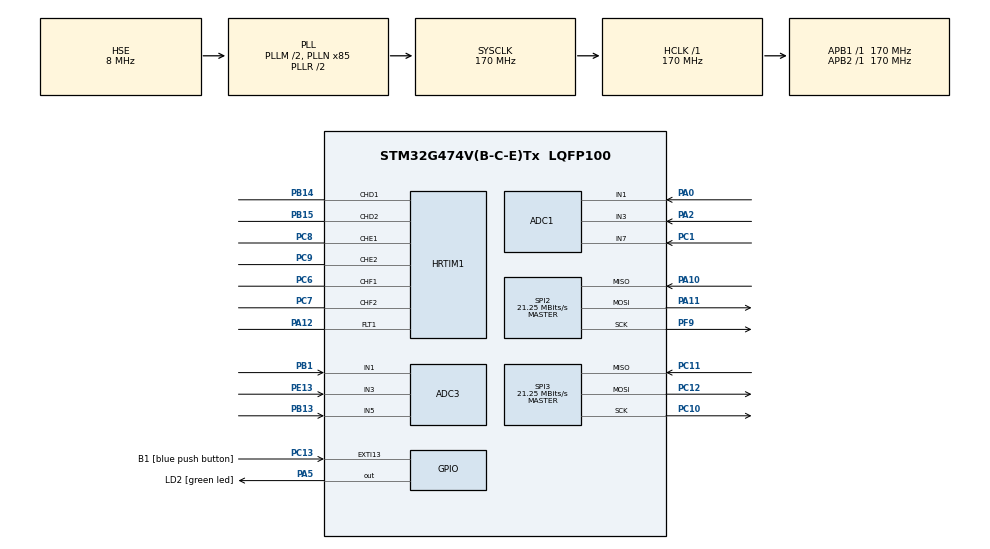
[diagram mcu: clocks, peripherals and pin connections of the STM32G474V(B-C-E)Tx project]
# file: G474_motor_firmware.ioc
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ADC1.AWD1HighThreshold=3
ADC1.AWD1ITMode=ENABLE
ADC1.ContinuousConvMode=ENABLE
ADC1.DMAContinuousRequests=ENABLE
ADC1.EOCSelection=ADC_EOC_SEQ_CONV
ADC1.EnableAnalogWatchDog1=true
ADC1.EnableInjectedConversion=ENABLE
ADC1.EnableInjectedOversampling=ENABLE
ADC1.EnableRegularConversion=DISABLE
ADC1.ExternalTrigInjecConv=ADC_EXTERNALTRIGINJEC_HRTIM_TRG2
ADC1.InjNumberOfConversion=3
ADC1.InjOversamplingRatio=ADC_OVERSAMPLING_RATIO_4
ADC1.InjOversamplingRightShift=ADC_RIGHTBITSHIFT_2
ADC1.InjectedChannel-1\#ChannelInjectedConversion=ADC_CHANNEL_1
ADC1.InjectedChannel-2\#ChannelInjectedConversion=ADC_CHANNEL_1
ADC1.InjectedChannel-3\#ChannelInjectedConversion=ADC_CHANNEL_1
ADC1.InjectedOffsetNumber-1\#ChannelInjectedConversion=ADC_OFFSET_NONE
ADC1.InjectedOffsetNumber-2\#ChannelInjectedConversion=ADC_OFFSET_NONE
ADC1.InjectedOffsetNumber-3\#ChannelInjectedConversion=ADC_OFFSET_NONE
ADC1.InjectedRank-1\#ChannelInjectedConversion=1
ADC1.InjectedRank-2\#ChannelInjectedConversion=2
ADC1.InjectedRank-3\#ChannelInjectedConversion=3
ADC1.InjectedSamplingTime-1\#ChannelInjectedConversion=ADC_SAMPLETIME_2CYCLES_5
ADC1.InjectedSamplingTime-2\#ChannelInjectedConversion=ADC_SAMPLETIME_2CYCLES_5
ADC1.InjectedSamplingTime-3\#ChannelInjectedConversion=ADC_SAMPLETIME_2CYCLES_5
ADC1.Rank1_Channel=ADC_CHANNEL_1
ADC1.Rank2_Channel=ADC_CHANNEL_1
ADC1.Rank3_Channel=ADC_CHANNEL_1
ADC1.WatchdogMode=ADC_ANALOGWATCHDOG_ALL_REGINJEC
ADC1.master=1
ADC3.AWD1HighThreshold=3
ADC3.AWD1ITMode=ENABLE
ADC3.ContinuousConvMode=ENABLE
ADC3.DMAContinuousRequests=ENABLE
ADC3.EOCSelection=ADC_EOC_SEQ_CONV
ADC3.EnableAnalogWatchDog1=true
ADC3.EnableInjectedConversion=ENABLE
ADC3.EnableInjectedOversampling=ENABLE
ADC3.EnableRegularConversion=DISABLE
ADC3.ExternalTrigInjecConv=ADC_EXTERNALTRIGINJEC_HRTIM_TRG2
ADC3.InjNumberOfConversion=3
ADC3.InjOversamplingRatio=ADC_OVERSAMPLING_RATIO_4
ADC3.InjOversamplingRightShift=ADC_RIGHTBITSHIFT_2
ADC3.InjectedChannel-1\#ChannelInjectedConversion=ADC_CHANNEL_1
ADC3.InjectedChannel-2\#ChannelInjectedConversion=ADC_CHANNEL_1
ADC3.InjectedChannel-3\#ChannelInjectedConversion=ADC_CHANNEL_1
ADC3.InjectedOffsetNumber-1\#ChannelInjectedConversion=ADC_OFFSET_NONE
ADC3.InjectedOffsetNumber-2\#ChannelInjectedConversion=ADC_OFFSET_NONE
ADC3.InjectedOffsetNumber-3\#ChannelInjectedConversion=ADC_OFFSET_NONE
ADC3.InjectedRank-1\#ChannelInjectedConversion=1
ADC3.InjectedRank-2\#ChannelInjectedConversion=2
ADC3.InjectedRank-3\#ChannelInjectedConversion=3
ADC3.InjectedSamplingTime-1\#ChannelInjectedConversion=ADC_SAMPLETIME_2CYCLES_5
ADC3.InjectedSamplingTime-2\#ChannelInjectedConversion=ADC_SAMPLETIME_2CYCLES_5
ADC3.InjectedSamplingTime-3\#ChannelInjectedConversion=ADC_SAMPLETIME_2CYCLES_5
ADC3.Rank1_Channel=ADC_CHANNEL_1
ADC3.Rank2_Channel=ADC_CHANNEL_1
ADC3.Rank3_Channel=ADC_CHANNEL_1
ADC3.WatchdogMode=ADC_ANALOGWATCHDOG_ALL_REGINJEC
ADC3.master=1
Dma.ADC1.0.Direction=DMA_PERIPH_TO_MEMORY
Dma.ADC1.0.EventEnable=DISABLE
Dma.ADC1.0.Instance=DMA1_Channel1
Dma.ADC1.0.MemDataAlignment=DMA_MDATAALIGN_HALFWORD
Dma.ADC1.0.MemInc=DMA_MINC_ENABLE
Dma.ADC1.0.Mode=DMA_CIRCULAR
Dma.ADC1.0.PeriphDataAlignment=DMA_PDATAALIGN_HALFWORD
Dma.ADC1.0.PeriphInc=DMA_PINC_DISABLE
Dma.ADC1.0.Polarity=HAL_DMAMUX_REQ_GEN_RISING
Dma.ADC1.0.Priority=DMA_PRIORITY_VERY_HIGH
Dma.ADC1.0.RequestNumber=1
Dma.ADC1.0.SignalID=NONE
Dma.ADC1.0.SyncEnable=DISABLE
Dma.ADC1.0.SyncPolarity=HAL_DMAMUX_SYNC_NO_EVENT
Dma.ADC1.0.SyncRequestNumber=1
Dma.ADC1.0.SyncSignalID=NONE
Dma.ADC3.1.Direction=DMA_PERIPH_TO_MEMORY
Dma.ADC3.1.EventEnable=DISABLE
Dma.ADC3.1.Instance=DMA1_Channel2
Dma.ADC3.1.MemDataAlignment=DMA_MDATAALIGN_HALFWORD
Dma.ADC3.1.MemInc=DMA_MINC_ENABLE
Dma.ADC3.1.Mode=DMA_CIRCULAR
Dma.ADC3.1.PeriphDataAlignment=DMA_PDATAALIGN_HALFWORD
Dma.ADC3.1.PeriphInc=DMA_PINC_DISABLE
Dma.ADC3.1.Polarity=HAL_DMAMUX_REQ_GEN_RISING
Dma.ADC3.1.Priority=DMA_PRIORITY_VERY_HIGH
Dma.ADC3.1.RequestNumber=1
Dma.ADC3.1.SignalID=NONE
Dma.ADC3.1.SyncEnable=DISABLE
Dma.ADC3.1.SyncPolarity=HAL_DMAMUX_SYNC_NO_EVENT
Dma.ADC3.1.SyncRequestNumber=1
Dma.ADC3.1.SyncSignalID=NONE
Dma.Request0=ADC1
Dma.Request1=ADC3
FREERTOS.Tasks01=defaultTask,24,128,StartDefaultTask,Default,NULL,Dynamic,NULL,NULL
FREERTOS.configENABLE_FPU=1
HRTIM1.ADCTrigger2_Source1=HRTIM_ADCTRIGGEREVENT24_MASTER_PERIOD
HRTIM1.ADCTrigger_Id1=__NULL
HRTIM1.ADCTrigger_Id10=__NULL
HRTIM1.ADCTrigger_Id2=HRTIM_ADCTRIGGER_2
HRTIM1.ADCTrigger_Id3=__NULL
HRTIM1.ADCTrigger_Id4=__NULL
HRTIM1.ADCTrigger_Id5=__NULL
HRTIM1.ADCTrigger_Id6=__NULL
HRTIM1.ADCTrigger_Id7=__NULL
HRTIM1.ADCTrigger_Id8=__NULL
HRTIM1.ADCTrigger_Id9=__NULL
HRTIM1.Adrom_TD=HRTIM_TIM_ADROM_VALLEY
HRTIM1.Adrom_TE=HRTIM_TIM_ADROM_VALLEY
HRTIM1.Adrom_TF=HRTIM_TIM_ADROM_VALLEY
HRTIM1.Bmrom_TD=HRTIM_TIM_BMROM_VALLEY
HRTIM1.Bmrom_TE=HRTIM_TIM_BMROM_VALLEY
HRTIM1.Bmrom_TF=HRTIM_TIM_BMROM_VALLEY
HRTIM1.BurstDMAconfig-MasterTimer=__NULL
HRTIM1.BurstDMAconfig-Output_TD1TD2=__NULL
HRTIM1.BurstMode-MasterTimer=HRTIM_TIMERBURSTMODE_MAINTAINCLOCK
HRTIM1.BurstMode-Output_TD1TD2=HRTIM_TIMERBURSTMODE_MAINTAINCLOCK
HRTIM1.BurstModeEntryDelayed1-Output_TD1TD2=HRTIM_OUTPUTBURSTMODEENTRY_REGULAR
HRTIM1.BurstModeEntryDelayed2-Output_TD1TD2=HRTIM_OUTPUTBURSTMODEENTRY_REGULAR
HRTIM1.CalibrationRate_nonIT=HRTIM_CALIBRATIONRATE_3
HRTIM1.CaptureUnit1-Output_TD1TD2=__NULL
HRTIM1.CaptureUnit2-Output_TD1TD2=__NULL
HRTIM1.ChopperModeEnable1-Output_TD1TD2=HRTIM_OUTPUTCHOPPERMODE_DISABLED
HRTIM1.ChopperModeEnable2-Output_TD1TD2=HRTIM_OUTPUTCHOPPERMODE_DISABLED
HRTIM1.ChopperModeconfig-Output_TD1TD2=__NULL
HRTIM1.CompareUnit1-MasterTimer=__NULL
HRTIM1.CompareUnit1-Output_TD1TD2=HRTIM_COMPAREUNIT_1
HRTIM1.CompareUnit1-Output_TE1TE2=HRTIM_COMPAREUNIT_1
HRTIM1.CompareUnit1-Output_TF1TF2=HRTIM_COMPAREUNIT_1
HRTIM1.CompareUnit2-MasterTimer=__NULL
HRTIM1.CompareUnit2-Output_TD1TD2=__NULL
HRTIM1.CompareUnit3-MasterTimer=__NULL
HRTIM1.CompareUnit3-Output_TD1TD2=__NULL
HRTIM1.CompareUnit4-MasterTimer=__NULL
HRTIM1.CompareUnit4-Output_TD1TD2=__NULL
HRTIM1.CompareValue1-Output_TD1TD2=TIMD_PERIOD * TIMD_DUTY_CYCLE
HRTIM1.CompareValue1-Output_TE1TE2=TIMD_PERIOD * TIMD_DUTY_CYCLE
HRTIM1.CompareValue1-Output_TF1TF2=TIMD_PERIOD * TIMD_DUTY_CYCLE
HRTIM1.Configuration_TD=Waveform
HRTIM1.DACSynchro-MasterTimer=HRTIM_DACSYNC_NONE
HRTIM1.DACSynchro-Output_TD1TD2=HRTIM_DACSYNC_NONE
HRTIM1.DeadTimeInsertion-Output_TD1TD2=HRTIM_TIMDEADTIMEINSERTION_ENABLED
HRTIM1.DeadTimeInsertion-Output_TE1TE2=HRTIM_TIMDEADTIMEINSERTION_ENABLED
HRTIM1.DeadTimeInsertion-Output_TF1TF2=HRTIM_TIMDEADTIMEINSERTION_ENABLED
HRTIM1.Deadtimeconfig-Output_TD1TD2=HRTIM_TIMERINDEX_TIMER_D
HRTIM1.DelayedProtectionMode-Output_TD1TD2=HRTIM_TIMER_D_E_DELAYEDPROTECTION_DISABLED
HRTIM1.DualChannelDacEnableFake_TD-Output_TD1TD2=HRTIM_TIMER_DCDE_DISABLED
HRTIM1.Enable=HRTIM_BURSTMODECTL_DISABLED
HRTIM1.EnableCalibration=DLLSimpleCalibration
HRTIM1.Event1-Output_TD1TD2=__NULL
HRTIM1.Event10-Output_TD1TD2=__NULL
HRTIM1.Event2-Output_TD1TD2=__NULL
HRTIM1.Event3-Output_TD1TD2=__NULL
HRTIM1.Event4-Output_TD1TD2=__NULL
HRTIM1.Event5-Output_TD1TD2=__NULL
HRTIM1.Event6-Output_TD1TD2=__NULL
HRTIM1.Event7-Output_TD1TD2=__NULL
HRTIM1.Event8-Output_TD1TD2=__NULL
HRTIM1.Event9-Output_TD1TD2=__NULL
HRTIM1.EventEnableA-Output_TD1TD2=__NULL
HRTIM1.Event_EEV1=__NULL
HRTIM1.Event_EEV10=__NULL
HRTIM1.Event_EEV2=__NULL
HRTIM1.Event_EEV3=__NULL
HRTIM1.Event_EEV4=__NULL
HRTIM1.Event_EEV5=__NULL
HRTIM1.Event_EEV6=__NULL
HRTIM1.Event_EEV7=__NULL
HRTIM1.Event_EEV8=__NULL
HRTIM1.Event_EEV9=__NULL
HRTIM1.FallingValue-Output_TD1TD2=10
HRTIM1.FallingValue-Output_TE1TE2=10
HRTIM1.FallingValue-Output_TF1TF2=10
HRTIM1.FaultEnable_Source1-Output_TD1TD2=HRTIM_TIMFAULTENABLE_FAULT1
HRTIM1.FaultEnable_Source1-Output_TE1TE2=HRTIM_TIMFAULTENABLE_FAULT1
HRTIM1.FaultEnable_Source1-Output_TF1TF2=HRTIM_TIMFAULTENABLE_FAULT1
HRTIM1.FaultLevel1-Output_TD1TD2=HRTIM_OUTPUTFAULTLEVEL_NONE
HRTIM1.FaultLevel2-Output_TD1TD2=HRTIM_OUTPUTFAULTLEVEL_NONE
HRTIM1.FaultLock-Output_TD1TD2=HRTIM_TIMFAULTLOCK_READWRITE
HRTIM1.Fault_Line1=HRTIM_FAULT_1
HRTIM1.Fault_Line2=__NULL
HRTIM1.Fault_Line3=__NULL
HRTIM1.Fault_Line4=__NULL
HRTIM1.Fault_Line5=__NULL
HRTIM1.Fault_Line6=__NULL
HRTIM1.Ferom_TD=HRTIM_TIM_FEROM_VALLEY
HRTIM1.Ferom_TE=HRTIM_TIM_FEROM_VALLEY
HRTIM1.Ferom_TF=HRTIM_TIM_FEROM_VALLEY
HRTIM1.Filter_FaultLine1=HRTIM_FAULTFILTER_3
HRTIM1.GreaterCMP1_TD=HRTIM_TIMERGTCMP1_EQUAL
HRTIM1.HRTIMInterruptResquests1=HRTIM_IT_NONE
HRTIM1.HRTIMInterruptResquests2=HRTIM_IT_NONE
HRTIM1.HRTIMInterruptResquests3=HRTIM_IT_NONE
HRTIM1.HRTIMInterruptResquests4=HRTIM_IT_NONE
HRTIM1.HRTIMInterruptResquests5=HRTIM_IT_NONE
HRTIM1.HRTIMInterruptResquests6=HRTIM_IT_NONE
HRTIM1.HRTIMInterruptResquests7=HRTIM_IT_NONE
HRTIM1.HRTIMInterruptResquests8=HRTIM_IT_NONE
HRTIM1.HRTIMInterruptResquests9=HRTIM_IT_NONE
HRTIM1.IdleLevel1-Output_TD1TD2=HRTIM_OUTPUTIDLELEVEL_INACTIVE
HRTIM1.IdleLevel2-Output_TD1TD2=HRTIM_OUTPUTIDLELEVEL_INACTIVE
HRTIM1.IdleMode1-Output_TD1TD2=HRTIM_OUTPUTIDLEMODE_NONE
HRTIM1.IdleMode2-Output_TD1TD2=HRTIM_OUTPUTIDLEMODE_NONE
HRTIM1.InterleavedMode-MasterTimer=HRTIM_INTERLEAVED_MODE_DISABLED
HRTIM1.InterleavedMode-Output_TD1TD2=HRTIM_INTERLEAVED_MODE_DISABLED
HRTIM1.ModeTimeBase-MasterTimer=HRTIM_MODE_CONTINUOUS
HRTIM1.ModeTimeBase-Output_TD1TD2=HRTIM_MODE_CONTINUOUS
HRTIM1.NumberADCTriggerSource2=1
HRTIM1.NumberDMARequests_Master=0
HRTIM1.NumberDMARequests_TD=0
HRTIM1.NumberFaultEnable-Output_TD1TD2=1
HRTIM1.NumberFaultEnable-Output_TE1TE2=1
HRTIM1.NumberFaultEnable-Output_TF1TF2=1
HRTIM1.NumberInterruptRequests-Output_TD1TD2=0
HRTIM1.NumberInterruptRequests_Master-MasterTimer=0
HRTIM1.NumberResetSource1-Output_TD1TD2=1
HRTIM1.NumberResetSource1-Output_TE1TE2=1
HRTIM1.NumberResetSource1-Output_TF1TF2=1
HRTIM1.NumberResetSource2_TD=0
HRTIM1.NumberResetTrigger-Output_TD1TD2=1
HRTIM1.NumberResetTrigger-Output_TE1TE2=1
HRTIM1.NumberResetTrigger-Output_TF1TF2=1
HRTIM1.NumberSetSource1-Output_TD1TD2=0
HRTIM1.NumberSetSource1-Output_TF1TF2=0
HRTIM1.NumberUpdateTrigger-Output_TD1TD2=0
HRTIM1.NumberUpdateTrigger-Output_TE1TE2=1
HRTIM1.Output1-Output_TD1TD2=HRTIM_OUTPUT_TD1
HRTIM1.Output2-Output_TD1TD2=HRTIM_OUTPUT_TD2
HRTIM1.Outrom_TD=HRTIM_TIM_OUTROM_VALLEY
HRTIM1.Outrom_TE=HRTIM_TIM_OUTROM_VALLEY
HRTIM1.Outrom_TF=HRTIM_TIM_OUTROM_VALLEY
HRTIM1.Periode_MASTER=MASTER_PERIOD
HRTIM1.Periode_TD=TIMD_PERIOD
HRTIM1.Periode_TE=TIMD_PERIOD
HRTIM1.Periode_TF=TIMD_PERIOD
HRTIM1.Polarity1-Output_TD1TD2=HRTIM_OUTPUTPOLARITY_HIGH
HRTIM1.Polarity2-Output_TD1TD2=HRTIM_OUTPUTPOLARITY_HIGH
HRTIM1.PreloadEnable-MasterTimer=HRTIM_PRELOAD_DISABLED
HRTIM1.PreloadEnable-Output_TD1TD2=HRTIM_PRELOAD_ENABLED
HRTIM1.PreloadEnable-Output_TE1TE2=HRTIM_PRELOAD_ENABLED
HRTIM1.PreloadEnable-Output_TF1TF2=HRTIM_PRELOAD_ENABLED
HRTIM1.PrescalerRatio_MASTER=HRTIM_PRESCALERRATIO_MUL32
HRTIM1.PrescalerRatio_TD=HRTIM_PRESCALERRATIO_MUL32
HRTIM1.PushPull-Output_TD1TD2=HRTIM_TIMPUSHPULLMODE_DISABLED
HRTIM1.ReSyncUpdate-Output_TD1TD2=HRTIM_TIMERESYNC_UPDATE_UNCONDITIONAL
HRTIM1.RepetitionUpdate-MasterTimer=HRTIM_UPDATEONREPETITION_DISABLED
HRTIM1.RepetitionUpdate-Output_TD1TD2=HRTIM_UPDATEONREPETITION_DISABLED
HRTIM1.ResetOnSync-MasterTimer=HRTIM_SYNCRESET_DISABLED
HRTIM1.ResetOnSync-Output_TD1TD2=HRTIM_SYNCRESET_DISABLED
HRTIM1.ResetOutput1_Source1-Output_TD1TD2=HRTIM_OUTPUTRESET_TIMCMP1
HRTIM1.ResetOutput1_Source1-Output_TE1TE2=HRTIM_OUTPUTRESET_TIMCMP1
HRTIM1.ResetOutput1_Source1-Output_TF1TF2=HRTIM_OUTPUTRESET_TIMCMP1
HRTIM1.ResetTrigger1-Output_TD1TD2=HRTIM_TIMRESETTRIGGER_MASTER_PER
HRTIM1.ResetTrigger1-Output_TE1TE2=HRTIM_TIMRESETTRIGGER_MASTER_PER
HRTIM1.ResetTrigger1-Output_TF1TF2=HRTIM_TIMRESETTRIGGER_MASTER_PER
HRTIM1.ResetUpdate-Output_TD1TD2=HRTIM_TIMUPDATEONRESET_ENABLED
HRTIM1.ResetUpdate-Output_TE1TE2=HRTIM_TIMUPDATEONRESET_ENABLED
HRTIM1.ResetUpdate-Output_TF1TF2=HRTIM_TIMUPDATEONRESET_ENABLED
HRTIM1.RisingValue-Output_TD1TD2=10
HRTIM1.RisingValue-Output_TE1TE2=10
HRTIM1.RisingValue-Output_TF1TF2=10
HRTIM1.StartOnSync-MasterTimer=HRTIM_SYNCSTART_DISABLED
HRTIM1.StartOnSync-Output_TD1TD2=HRTIM_SYNCSTART_DISABLED
HRTIM1.SwapD=__NULL
HRTIM1.SyncOptions=HRTIM_SYNCOPTION_NONE
HRTIM1.Timeout=10
HRTIM1.TimerIdx-MasterTimer=HRTIM_TIMERINDEX_MASTER
HRTIM1.TimerIdx-Output_TD1TD2=HRTIM_TIMERINDEX_TIMER_D
HRTIM1.UpDownMode-Output_TD1TD2=HRTIM_TIMERUPDOWNMODE_UPDOWN
HRTIM1.UpDownMode-Output_TE1TE2=HRTIM_TIMERUPDOWNMODE_UPDOWN
HRTIM1.UpDownMode-Output_TF1TF2=HRTIM_TIMERUPDOWNMODE_UPDOWN
HRTIM1.UpdateGating-MasterTimer=HRTIM_UPDATEGATING_INDEPENDENT
HRTIM1.UpdateGating-Output_TD1TD2=HRTIM_UPDATEGATING_INDEPENDENT
HRTIM1.UpdateTrigger1-Output_TE1TE2=HRTIM_TIMUPDATETRIGGER_MASTER
HRTIM1.rom_TD=HRTIM_TIM_ROM_VALLEY
HRTIM1.rom_TE=HRTIM_TIM_ROM_VALLEY
HRTIM1.rom_TF=HRTIM_TIM_ROM_VALLEY
Mcu.Family=STM32G4
Mcu.Name=STM32G474V(B-C-E)Tx
Mcu.Package=LQFP100
Mcu.UserConstants=TIMD_PWM_FREQ,54400;TIMD_DUTY_CYCLE,0.75;HRTIM_INPUT_CLOCK,170000000;MASTER_DUTY_CYCLE,0.5;MASTER_PWM_FREQ,54400
NVIC.ADC1_2_IRQn=true\:1\:0\:true\:false\:true\:false\:true\:true\:true
NVIC.ADC3_IRQn=true\:1\:0\:true\:false\:true\:false\:true\:true\:true
NVIC.DMA1_Channel1_IRQn=true\:0\:0\:false\:false\:true\:false\:false\:true\:true
NVIC.DMA1_Channel2_IRQn=true\:0\:0\:false\:false\:true\:false\:false\:true\:true
NVIC.EXTI15_10_IRQn=true\:1\:0\:true\:false\:true\:false\:true\:true\:true
NVIC.HRTIM1_FLT_IRQn=true\:2\:0\:true\:false\:true\:false\:true\:true\:true
NVIC.PriorityGroup=NVIC_PRIORITYGROUP_4
NVIC.TIM2_IRQn=true\:15\:0\:false\:false\:true\:false\:false\:true\:true
NVIC.TimeBase=TIM2_IRQn
NVIC.TimeBaseIP=TIM2
PA0.Mode=IN1-Single-Ended
PA0.Signal=ADC1_IN1
PA10.Mode=Full_Duplex_Master
PA10.Signal=SPI2_MISO
PA11.Mode=Full_Duplex_Master
PA11.Signal=SPI2_MOSI
PA12.Mode=Fault_Enable1
PA12.Signal=HRTIM1_FLT1
PA13.GPIO_Label=T_SWDIO
PA13.Mode=Serial_Wire
PA13.Signal=SYS_JTMS-SWDIO
PA14.GPIO_Label=T_SWCLK
PA14.Mode=Serial_Wire
PA14.Signal=SYS_JTCK-SWCLK
PA2.Mode=IN3-Single-Ended
PA2.Signal=ADC1_IN3
PA5.GPIO_Label=LD2 [green led]
PA5.Signal=GPIO_Output
PB1.Mode=IN1-Single-Ended
PB1.Signal=ADC3_IN1
PB13.Mode=IN5-Single-Ended
PB13.Signal=ADC3_IN5
PB14.Mode=Output_TD1TD2
PB14.Signal=HRTIM1_CHD1
PB15.Mode=Output_TD1TD2
PB15.Signal=HRTIM1_CHD2
PB3.GPIO_Label=T_SWO
PB3.Signal=SYS_JTDO-SWO
PC1.Mode=IN7-Single-Ended
PC1.Signal=ADC1_IN7
PC10.Mode=Full_Duplex_Master
PC10.Signal=SPI3_SCK
PC11.Mode=Full_Duplex_Master
PC11.Signal=SPI3_MISO
PC12.Mode=Full_Duplex_Master
PC12.Signal=SPI3_MOSI
PC13.GPIO_Label=B1 [blue push button]
PC13.Signal=GPXTI13
PC14-OSC32_IN.Signal=RCC_OSC32_IN
PC15-OSC32_OUT.Signal=RCC_OSC32_OUT
PC4.GPIO_Label=USART1_TX [STLINKV3E_VCP_RX]
PC4.Signal=USART1_TX
PC5.GPIO_Label=USART1_RX [STLINKV3E_VCP_TX]
PC5.Signal=USART1_RX
PC6.Mode=Output_TF1TF2
PC6.Signal=HRTIM1_CHF1
PC7.Mode=Output_TF1TF2
PC7.Signal=HRTIM1_CHF2
PC8.Mode=Output_TE1TE2
PC8.Signal=HRTIM1_CHE1
PC9.Mode=Output_TE1TE2
PC9.Signal=HRTIM1_CHE2
PE13.Mode=IN3-Single-Ended
PE13.Signal=ADC3_IN3
PF0-OSC_IN.Mode=HSE-External-Oscillator
PF0-OSC_IN.Signal=RCC_OSC_IN
PF1-OSC_OUT.Mode=HSE-External-Oscillator
PF1-OSC_OUT.Signal=RCC_OSC_OUT
PF9.Mode=Full_Duplex_Master
PF9.Signal=SPI2_SCK
ProjectManager.HeapSize=0x200
ProjectManager.StackSize=0x400
ProjectManager.TargetToolchain=CMake
RCC.ADC12Freq_Value=170000000
RCC.ADC345Freq_Value=170000000
RCC.AHBFreq_Value=170000000
RCC.APB1Freq_Value=170000000
RCC.APB1TimFreq_Value=170000000
RCC.APB2Freq_Value=170000000
RCC.APB2TimFreq_Value=170000000
RCC.CK48CLockSelection=RCC_USBCLKSOURCE_HSI48
RCC.CortexFreq_Value=170000000
RCC.EXTERNAL_CLOCK_VALUE=12288000
RCC.FLatency=FLASH_LATENCY_4
RCC.HCLKFreq_Value=170000000
RCC.HSE_VALUE=8000000
RCC.HSI48_VALUE=48000000
RCC.HSI_VALUE=16000000
RCC.LSE_VALUE=32768
RCC.PLLM=RCC_PLLM_DIV2
RCC.PLLN=85
RCC.PLLQ=RCC_PLLQ_DIV8
RCC.PLLSourceVirtual=RCC_PLLSOURCE_HSE
RCC.PWR_Regulator_Voltage_Scale=PWR_REGULATOR_VOLTAGE_SCALE1_BOOST
RCC.SYSCLKFreq_VALUE=170000000
RCC.SYSCLKSource=RCC_SYSCLKSOURCE_PLLCLK
RCC.USBFreq_Value=48000000
RCC.VCOOutputFreq_Value=340000000
SPI2.BaudRatePrescaler=SPI_BAUDRATEPRESCALER_8
SPI2.CalculateBaudRate=21.25 MBits/s
SPI2.Direction=SPI_DIRECTION_2LINES
SPI2.Mode=SPI_MODE_MASTER
SPI2.VirtualType=VM_MASTER
SPI3.BaudRatePrescaler=SPI_BAUDRATEPRESCALER_8
SPI3.CalculateBaudRate=21.25 MBits/s
SPI3.Direction=SPI_DIRECTION_2LINES
SPI3.Mode=SPI_MODE_MASTER
SPI3.VirtualType=VM_MASTER
VP_CORDIC_VS_CORDIC.Mode=CORDIC_Activate
VP_CRC_VS_CRC.Mode=CRC_Activate
VP_FMAC_VS_FMAC.Mode=FMAC_Activate
VP_FREERTOS_VS_CMSIS_V2.Mode=CMSIS_V2
VP_HRTIM1_VS_hrtimMasterTimerNoOutput.Mode=MasterTimer
VP_RNG_VS_RNG.Mode=RNG_Activate
VP_SYS_VS_DBSignals.Mode=DisableDeadBatterySignals
VP_SYS_VS_tim2.Mode=TIM2
board=NUCLEO-G474RE

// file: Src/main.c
/* USER CODE BEGIN Header */
/**
  ******************************************************************************
  * @file           : main.c
  * @brief          : Main program body
  ******************************************************************************
  * @attention
  *
  * Copyright (c) 2026 STMicroelectronics.
  * All rights reserved.
  *
  * This software is licensed under terms that can be found in the LICENSE file
  * in the root directory of this software component.
  * If no LICENSE file comes with this software, it is provided AS-IS.
  *
  ******************************************************************************
  */
/* USER CODE END Header */
#include "main.h"
#include "cmsis_os.h"
#include "adc.h"
#include "cordic.h"
#include "crc.h"
#include "dma.h"
#include "fmac.h"
#include "hrtim.h"
#include "rng.h"
#include "spi.h"
#include "gpio.h"

void SystemClock_Config(void);
void MX_FREERTOS_Init(void);

int main(void)
{

  /* MCU Configuration--------------------------------------------------------*/

  /* Reset of all peripherals, Initializes the Flash interface and the Systick. */
  HAL_Init();

  /* Configure the system clock */
  SystemClock_Config();

  /* Initialize all configured peripherals */
  MX_GPIO_Init();
  MX_DMA_Init();
  MX_HRTIM1_Init();
  MX_ADC1_Init();
  MX_ADC3_Init();
  MX_CORDIC_Init();
  MX_CRC_Init();
  MX_FMAC_Init();
  MX_RNG_Init();
  MX_SPI2_Init();
  MX_SPI3_Init();
  /* USER CODE BEGIN 2 */
  /* Enable HRTIM's outputs TD1 and TD2 */
  HAL_HRTIM_WaveformOutputStart(&hhrtim1, HRTIM_OUTPUT_TD1 + HRTIM_OUTPUT_TD2 + HRTIM_OUTPUT_TE1 + HRTIM_OUTPUT_TE2 + HRTIM_OUTPUT_TF1 + HRTIM_OUTPUT_TF2);
  /* Start HRTIM's Master TIMER and TIMER D*/
  HAL_HRTIM_WaveformCounterStart(&hhrtim1, HRTIM_TIMERID_MASTER + HRTIM_TIMERID_TIMER_D + HRTIM_TIMERID_TIMER_E + HRTIM_TIMERID_TIMER_F);
  /* USER CODE END 2 */

  /* Init scheduler */
  osKernelInitialize();  /* Call init function for freertos objects (in cmsis_os2.c) */
  MX_FREERTOS_Init();

  /* Start scheduler */
  osKernelStart();

  /* We should never get here as control is now taken by the scheduler */

  /* Infinite loop */
  while (1)
  {

  }
}

void SystemClock_Config(void)
{
  RCC_OscInitTypeDef RCC_OscInitStruct = {0};
  RCC_ClkInitTypeDef RCC_ClkInitStruct = {0};

  /** Configure the main internal regulator output voltage
  */
  HAL_PWREx_ControlVoltageScaling(PWR_REGULATOR_VOLTAGE_SCALE1_BOOST);

  /** Initializes the RCC Oscillators according to the specified parameters
  * in the RCC_OscInitTypeDef structure.
  */
  RCC_OscInitStruct.OscillatorType = RCC_OSCILLATORTYPE_HSI48|RCC_OSCILLATORTYPE_HSE;
  RCC_OscInitStruct.HSEState = RCC_HSE_ON;
  RCC_OscInitStruct.HSI48State = RCC_HSI48_ON;
  RCC_OscInitStruct.PLL.PLLState = RCC_PLL_ON;
  RCC_OscInitStruct.PLL.PLLSource = RCC_PLLSOURCE_HSE;
  RCC_OscInitStruct.PLL.PLLM = RCC_PLLM_DIV2;
  RCC_OscInitStruct.PLL.PLLN = 85;
  RCC_OscInitStruct.PLL.PLLP = RCC_PLLP_DIV2;
  RCC_OscInitStruct.PLL.PLLQ = RCC_PLLQ_DIV8;
  RCC_OscInitStruct.PLL.PLLR = RCC_PLLR_DIV2;
  if (HAL_RCC_OscConfig(&RCC_OscInitStruct) != HAL_OK)
  {
    Error_Handler();
  }

  /** Initializes the CPU, AHB and APB buses clocks
  */
  RCC_ClkInitStruct.ClockType = RCC_CLOCKTYPE_HCLK|RCC_CLOCKTYPE_SYSCLK
                              |RCC_CLOCKTYPE_PCLK1|RCC_CLOCKTYPE_PCLK2;
  RCC_ClkInitStruct.SYSCLKSource = RCC_SYSCLKSOURCE_PLLCLK;
  RCC_ClkInitStruct.AHBCLKDivider = RCC_SYSCLK_DIV1;
  RCC_ClkInitStruct.APB1CLKDivider = RCC_HCLK_DIV1;
  RCC_ClkInitStruct.APB2CLKDivider = RCC_HCLK_DIV1;

  if (HAL_RCC_ClockConfig(&RCC_ClkInitStruct, FLASH_LATENCY_4) != HAL_OK)
  {
    Error_Handler();
  }
}

void HAL_TIM_PeriodElapsedCallback(TIM_HandleTypeDef *htim)
{
  if (htim->Instance == TIM2)
  {
    HAL_IncTick();
  }
}

void Error_Handler(void)
{
  __disable_irq();
  while (1)
  {
  }
}
